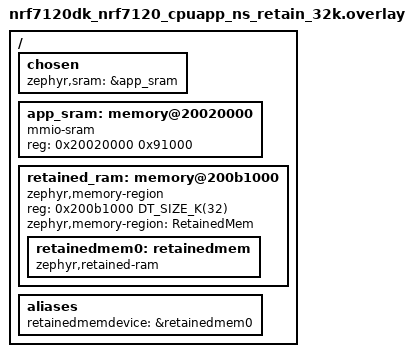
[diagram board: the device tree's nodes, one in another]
#include "nrf7120dk_nrf7120_cpuapp_ns.overlay"

/ {
	chosen {
		zephyr,sram = &app_sram;
	};

	app_sram: memory@20020000 {
		compatible = "mmio-sram";
		reg = <0x20020000 0x91000>;
	};

	retained_ram: memory@200b1000 {
		compatible = "zephyr,memory-region", "mmio-sram";
		reg = <0x200b1000 DT_SIZE_K(32)>;
		zephyr,memory-region = "RetainedMem";
		status = "okay";

		retainedmem0: retainedmem {
			compatible = "zephyr,retained-ram";
			status = "okay";
		};
	};

	aliases {
		retainedmemdevice = &retainedmem0;
	};
};
